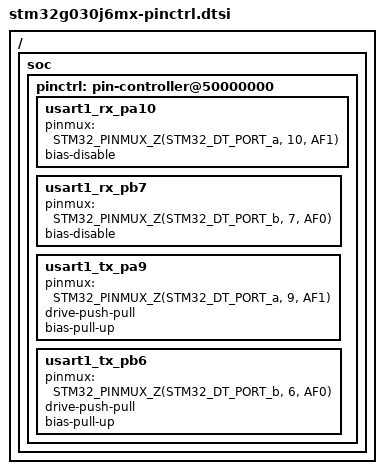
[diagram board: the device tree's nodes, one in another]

/*
 * NOTE: Autogenerated file using stm32_pinctrl_gen.py
 *
 * SPDX-License-Identifier: Apache-2.0
 */

#include <dt-bindings/pinctrl/stm32-pinctrl.h>

/ {
	soc {
		pinctrl: pin-controller@50000000 {
			/* UART_RX */
			usart1_rx_pa10: usart1_rx_pa10 {
				pinmux = <STM32_PINMUX_Z(STM32_DT_PORT_a, 10, AF1)>;
				bias-disable;
			};

			usart1_rx_pb7: usart1_rx_pb7 {
				pinmux = <STM32_PINMUX_Z(STM32_DT_PORT_b, 7, AF0)>;
				bias-disable;
			};


			/* UART_TX */
			usart1_tx_pa9: usart1_tx_pa9 {
				pinmux = <STM32_PINMUX_Z(STM32_DT_PORT_a, 9, AF1)>;
				drive-push-pull;
				bias-pull-up;
			};

			usart1_tx_pb6: usart1_tx_pb6 {
				pinmux = <STM32_PINMUX_Z(STM32_DT_PORT_b, 6, AF0)>;
				drive-push-pull;
				bias-pull-up;
			};

		};
	};
};
